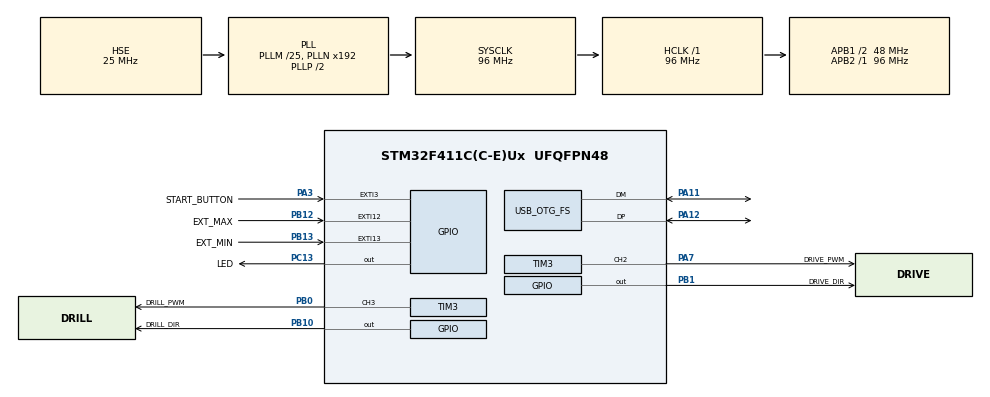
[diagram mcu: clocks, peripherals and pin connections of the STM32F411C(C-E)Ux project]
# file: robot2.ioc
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FREERTOS.Tasks01=control,32,512,TaskControl,As external,NULL,Dynamic,NULL,NULL;terminal,8,1024,TaskTerminal,As external,NULL,Dynamic,NULL,NULL;drive,40,512,TaskDrive,As external,NULL,Dynamic,NULL,NULL;rotate,40,512,TaskRotate,As external,NULL,Dynamic,NULL,NULL
FREERTOS.configCHECK_FOR_STACK_OVERFLOW=2
FREERTOS.configTOTAL_HEAP_SIZE=32768
FREERTOS.configUSE_MALLOC_FAILED_HOOK=1
FREERTOS.configUSE_NEWLIB_REENTRANT=1
Mcu.Family=STM32F4
Mcu.Name=STM32F411C(C-E)Ux
Mcu.Package=UFQFPN48
NVIC.EXTI15_10_IRQn=true\:5\:0\:true\:false\:true\:true\:true\:true\:true
NVIC.EXTI3_IRQn=true\:5\:0\:true\:false\:true\:true\:true\:true\:true
NVIC.OTG_FS_IRQn=true\:5\:0\:false\:false\:true\:true\:false\:true\:true
NVIC.PriorityGroup=NVIC_PRIORITYGROUP_4
NVIC.TIM1_UP_TIM10_IRQn=true\:15\:0\:false\:false\:true\:false\:false\:true\:true
NVIC.TimeBase=TIM1_UP_TIM10_IRQn
NVIC.TimeBaseIP=TIM10
PA11.Mode=Device_Only
PA11.Signal=USB_OTG_FS_DM
PA12.Mode=Device_Only
PA12.Signal=USB_OTG_FS_DP
PA3.GPIO_Label=START_BUTTON
PA3.GPIO_PuPd=GPIO_PULLDOWN
PA3.Signal=GPXTI3
PA7.GPIO_Label=DRIVE_PWM
PA7.Signal=S_TIM3_CH2
PB0.GPIO_Label=DRILL_PWM
PB0.Signal=S_TIM3_CH3
PB1.GPIO_Label=DRIVE_DIR
PB1.Signal=GPIO_Output
PB10.GPIO_Label=DRILL_DIR
PB10.PinState=GPIO_PIN_SET
PB10.Signal=GPIO_Output
PB12.GPIO_Label=EXT_MAX
PB12.GPIO_ModeDefaultEXTI=GPIO_MODE_IT_RISING_FALLING
PB12.GPIO_PuPd=GPIO_PULLDOWN
PB12.Signal=GPXTI12
PB13.GPIO_Label=EXT_MIN
PB13.GPIO_ModeDefaultEXTI=GPIO_MODE_IT_RISING_FALLING
PB13.GPIO_PuPd=GPIO_PULLDOWN
PB13.Signal=GPXTI13
PC13-ANTI_TAMP.GPIO_Label=LED
PC13-ANTI_TAMP.GPIO_PuPd=GPIO_PULLDOWN
PC13-ANTI_TAMP.PinState=GPIO_PIN_SET
PC13-ANTI_TAMP.Signal=GPIO_Output
PC14-OSC32_IN.Mode=LSE-External-Oscillator
PC14-OSC32_IN.Signal=RCC_OSC32_IN
PC15-OSC32_OUT.Mode=LSE-External-Oscillator
PC15-OSC32_OUT.Signal=RCC_OSC32_OUT
PH0\ -\ OSC_IN.Mode=HSE-External-Oscillator
PH0\ -\ OSC_IN.Signal=RCC_OSC_IN
PH1\ -\ OSC_OUT.Mode=HSE-External-Oscillator
PH1\ -\ OSC_OUT.Signal=RCC_OSC_OUT
ProjectManager.HeapSize=0x200
ProjectManager.StackSize=0x400
ProjectManager.TargetToolchain=CMake
RCC.48MHZClocksFreq_Value=48000000
RCC.AHBFreq_Value=96000000
RCC.APB1CLKDivider=RCC_HCLK_DIV2
RCC.APB1Freq_Value=48000000
RCC.APB1TimFreq_Value=96000000
RCC.APB2Freq_Value=96000000
RCC.APB2TimFreq_Value=96000000
RCC.CortexFreq_Value=96000000
RCC.HCLKFreq_Value=96000000
RCC.HSE_VALUE=25000000
RCC.HSI_VALUE=16000000
RCC.PLLM=25
RCC.SYSCLKFreq_VALUE=96000000
RCC.SYSCLKSource=RCC_SYSCLKSOURCE_PLLCLK
RCC.VCOOutputFreq_Value=192000000
SH.S_TIM3_CH2.0=TIM3_CH2,PWM Generation2 CH2
SH.S_TIM3_CH3.0=TIM3_CH3,PWM Generation3 CH3
TIM3.Channel-PWM\ Generation2\ CH2=TIM_CHANNEL_2
TIM3.Channel-PWM\ Generation3\ CH3=TIM_CHANNEL_3
TIM3.OCPolarity_3=TIM_OCPOLARITY_LOW
TIM3.Period=4799
USB_DEVICE.CLASS_NAME_FS=CDC
USB_DEVICE.VirtualMode=Cdc
USB_DEVICE.VirtualModeFS=Cdc_FS
USB_OTG_FS.VirtualMode=Device_Only
VP_FREERTOS_VS_CMSIS_V2.Mode=CMSIS_V2
VP_SYS_VS_tim10.Mode=TIM10
VP_TIM3_VS_ClockSourceINT.Mode=Internal
VP_USB_DEVICE_VS_USB_DEVICE_CDC_FS.Mode=CDC_FS
board=custom

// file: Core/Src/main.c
/* USER CODE BEGIN Header */
/**
  ******************************************************************************
  * @file           : main.c
  * @brief          : Main program body
  ******************************************************************************
  * @attention
  *
  * Copyright (c) 2026 STMicroelectronics.
  * All rights reserved.
  *
  * This software is licensed under terms that can be found in the LICENSE file
  * in the root directory of this software component.
  * If no LICENSE file comes with this software, it is provided AS-IS.
  *
  ******************************************************************************
  */
/* USER CODE END Header */
#include "main.h"
#include "cmsis_os.h"
#include "usb_device.h"

/* USER CODE BEGIN Includes */
#include "app.h"
/* USER CODE END Includes */

TIM_HandleTypeDef htim3;

/* Definitions for control */
osThreadId_t controlHandle;
const osThreadAttr_t control_attributes = {
  .name = "control",
  .stack_size = 512 * 4,
  .priority = (osPriority_t) osPriorityAboveNormal,
};
/* Definitions for terminal */
osThreadId_t terminalHandle;
const osThreadAttr_t terminal_attributes = {
  .name = "terminal",
  .stack_size = 1024 * 4,
  .priority = (osPriority_t) osPriorityLow,
};
/* Definitions for drive */
osThreadId_t driveHandle;
const osThreadAttr_t drive_attributes = {
  .name = "drive",
  .stack_size = 512 * 4,
  .priority = (osPriority_t) osPriorityHigh,
};
/* Definitions for rotate */
osThreadId_t rotateHandle;
const osThreadAttr_t rotate_attributes = {
  .name = "rotate",
  .stack_size = 512 * 4,
  .priority = (osPriority_t) osPriorityHigh,
};

void SystemClock_Config(void);
static void MX_GPIO_Init(void);
static void MX_TIM3_Init(void);
extern void TaskControl(void *argument);
extern void TaskTerminal(void *argument);
extern void TaskDrive(void *argument);
extern void TaskRotate(void *argument);

int main(void)
{

  /* MCU Configuration--------------------------------------------------------*/

  /* Reset of all peripherals, Initializes the Flash interface and the Systick. */
  HAL_Init();

  /* Configure the system clock */
  SystemClock_Config();

  /* Initialize all configured peripherals */
  MX_GPIO_Init();
  MX_TIM3_Init();
  /* USER CODE BEGIN 2 */
  app_init_early();         /* before USB starts: the USB interrupt uses it */
  MX_USB_DEVICE_Init();     /* CubeMX only calls it from its weak TaskControl, which ours replaces */
  /* USER CODE END 2 */

  /* Init scheduler */
  osKernelInitialize();

  /* USER CODE BEGIN RTOS_QUEUES */
  app_init_rtos();
  /* USER CODE END RTOS_QUEUES */

  /* Create the thread(s) */
  /* creation of control */
  controlHandle = osThreadNew(TaskControl, NULL, &control_attributes);

  /* creation of terminal */
  terminalHandle = osThreadNew(TaskTerminal, NULL, &terminal_attributes);

  /* creation of drive */
  driveHandle = osThreadNew(TaskDrive, NULL, &drive_attributes);

  /* creation of rotate */
  rotateHandle = osThreadNew(TaskRotate, NULL, &rotate_attributes);

  /* Start scheduler */
  osKernelStart();

  /* We should never get here as control is now taken by the scheduler */

  /* Infinite loop */
  while (1)
  {

  }
}

void SystemClock_Config(void)
{
  RCC_OscInitTypeDef RCC_OscInitStruct = {0};
  RCC_ClkInitTypeDef RCC_ClkInitStruct = {0};

  /** Configure the main internal regulator output voltage
  */
  __HAL_RCC_PWR_CLK_ENABLE();
  __HAL_PWR_VOLTAGESCALING_CONFIG(PWR_REGULATOR_VOLTAGE_SCALE1);

  /** Initializes the RCC Oscillators according to the specified parameters
  * in the RCC_OscInitTypeDef structure.
  */
  RCC_OscInitStruct.OscillatorType = RCC_OSCILLATORTYPE_HSE;
  RCC_OscInitStruct.HSEState = RCC_HSE_ON;
  RCC_OscInitStruct.PLL.PLLState = RCC_PLL_ON;
  RCC_OscInitStruct.PLL.PLLSource = RCC_PLLSOURCE_HSE;
  RCC_OscInitStruct.PLL.PLLM = 25;
  RCC_OscInitStruct.PLL.PLLN = 192;
  RCC_OscInitStruct.PLL.PLLP = RCC_PLLP_DIV2;
  RCC_OscInitStruct.PLL.PLLQ = 4;
  if (HAL_RCC_OscConfig(&RCC_OscInitStruct) != HAL_OK)
  {
    Error_Handler();
  }

  /** Initializes the CPU, AHB and APB buses clocks
  */
  RCC_ClkInitStruct.ClockType = RCC_CLOCKTYPE_HCLK|RCC_CLOCKTYPE_SYSCLK
                              |RCC_CLOCKTYPE_PCLK1|RCC_CLOCKTYPE_PCLK2;
  RCC_ClkInitStruct.SYSCLKSource = RCC_SYSCLKSOURCE_PLLCLK;
  RCC_ClkInitStruct.AHBCLKDivider = RCC_SYSCLK_DIV1;
  RCC_ClkInitStruct.APB1CLKDivider = RCC_HCLK_DIV2;
  RCC_ClkInitStruct.APB2CLKDivider = RCC_HCLK_DIV1;

  if (HAL_RCC_ClockConfig(&RCC_ClkInitStruct, FLASH_LATENCY_3) != HAL_OK)
  {
    Error_Handler();
  }
}

static void MX_TIM3_Init(void)
{

  TIM_ClockConfigTypeDef sClockSourceConfig = {0};
  TIM_MasterConfigTypeDef sMasterConfig = {0};
  TIM_OC_InitTypeDef sConfigOC = {0};

  htim3.Instance = TIM3;
  htim3.Init.Prescaler = 0;
  htim3.Init.CounterMode = TIM_COUNTERMODE_UP;
  htim3.Init.Period = 4799;
  htim3.Init.ClockDivision = TIM_CLOCKDIVISION_DIV1;
  htim3.Init.AutoReloadPreload = TIM_AUTORELOAD_PRELOAD_DISABLE;
  if (HAL_TIM_Base_Init(&htim3) != HAL_OK)
  {
    Error_Handler();
  }
  sClockSourceConfig.ClockSource = TIM_CLOCKSOURCE_INTERNAL;
  if (HAL_TIM_ConfigClockSource(&htim3, &sClockSourceConfig) != HAL_OK)
  {
    Error_Handler();
  }
  if (HAL_TIM_PWM_Init(&htim3) != HAL_OK)
  {
    Error_Handler();
  }
  sMasterConfig.MasterOutputTrigger = TIM_TRGO_RESET;
  sMasterConfig.MasterSlaveMode = TIM_MASTERSLAVEMODE_DISABLE;
  if (HAL_TIMEx_MasterConfigSynchronization(&htim3, &sMasterConfig) != HAL_OK)
  {
    Error_Handler();
  }
  sConfigOC.OCMode = TIM_OCMODE_PWM1;
  sConfigOC.Pulse = 0;
  sConfigOC.OCPolarity = TIM_OCPOLARITY_HIGH;
  sConfigOC.OCFastMode = TIM_OCFAST_DISABLE;
  if (HAL_TIM_PWM_ConfigChannel(&htim3, &sConfigOC, TIM_CHANNEL_2) != HAL_OK)
  {
    Error_Handler();
  }
  sConfigOC.OCPolarity = TIM_OCPOLARITY_LOW;
  if (HAL_TIM_PWM_ConfigChannel(&htim3, &sConfigOC, TIM_CHANNEL_3) != HAL_OK)
  {
    Error_Handler();
  }
  HAL_TIM_MspPostInit(&htim3);

}

static void MX_GPIO_Init(void)
{
  GPIO_InitTypeDef GPIO_InitStruct = {0};

  /* GPIO Ports Clock Enable */
  __HAL_RCC_GPIOC_CLK_ENABLE();
  __HAL_RCC_GPIOH_CLK_ENABLE();
  __HAL_RCC_GPIOA_CLK_ENABLE();
  __HAL_RCC_GPIOB_CLK_ENABLE();

  /*Configure GPIO pin Output Level */
  HAL_GPIO_WritePin(LED_GPIO_Port, LED_Pin, GPIO_PIN_SET);

  /*Configure GPIO pin Output Level */
  HAL_GPIO_WritePin(DRIVE_DIR_GPIO_Port, DRIVE_DIR_Pin, GPIO_PIN_RESET);

  /*Configure GPIO pin Output Level */
  HAL_GPIO_WritePin(DRILL_DIR_GPIO_Port, DRILL_DIR_Pin, GPIO_PIN_SET);

  /*Configure GPIO pin : LED_Pin */
  GPIO_InitStruct.Pin = LED_Pin;
  GPIO_InitStruct.Mode = GPIO_MODE_OUTPUT_PP;
  GPIO_InitStruct.Pull = GPIO_PULLDOWN;
  GPIO_InitStruct.Speed = GPIO_SPEED_FREQ_LOW;
  HAL_GPIO_Init(LED_GPIO_Port, &GPIO_InitStruct);

  /*Configure GPIO pin : START_BUTTON_Pin */
  GPIO_InitStruct.Pin = START_BUTTON_Pin;
  GPIO_InitStruct.Mode = GPIO_MODE_IT_RISING;
  GPIO_InitStruct.Pull = GPIO_PULLDOWN;
  HAL_GPIO_Init(START_BUTTON_GPIO_Port, &GPIO_InitStruct);

  /*Configure GPIO pins : DRIVE_DIR_Pin DRILL_DIR_Pin */
  GPIO_InitStruct.Pin = DRIVE_DIR_Pin|DRILL_DIR_Pin;
  GPIO_InitStruct.Mode = GPIO_MODE_OUTPUT_PP;
  GPIO_InitStruct.Pull = GPIO_NOPULL;
  GPIO_InitStruct.Speed = GPIO_SPEED_FREQ_LOW;
  HAL_GPIO_Init(GPIOB, &GPIO_InitStruct);

  /*Configure GPIO pins : EXT_MAX_Pin EXT_MIN_Pin */
  GPIO_InitStruct.Pin = EXT_MAX_Pin|EXT_MIN_Pin;
  GPIO_InitStruct.Mode = GPIO_MODE_IT_RISING_FALLING;
  GPIO_InitStruct.Pull = GPIO_PULLDOWN;
  HAL_GPIO_Init(GPIOB, &GPIO_InitStruct);

  /* EXTI interrupt init*/
  HAL_NVIC_SetPriority(EXTI3_IRQn, 5, 0);
  HAL_NVIC_EnableIRQ(EXTI3_IRQn);

  HAL_NVIC_SetPriority(EXTI15_10_IRQn, 5, 0);
  HAL_NVIC_EnableIRQ(EXTI15_10_IRQn);

}

__weak void TaskControl(void *argument)
{
  /* init code for USB_DEVICE */
  MX_USB_DEVICE_Init();
  for(;;)
  {
    osDelay(1);
  }
}

void HAL_TIM_PeriodElapsedCallback(TIM_HandleTypeDef *htim)
{
  if (htim->Instance == TIM10)
  {
    HAL_IncTick();
  }
}

void Error_Handler(void)
{
  __disable_irq();
  while (1)
  {
  }
}
